# R7KA8P1AD register map
Vendor: Renesas Electronics Corporation; Series: RA8; File version: 1.10.02
CPU: CM85 r0p2, little endian, MPU, FPU, VTOR, 4 interrupt priority bits, 96 interrupts
Registers are 32-bit, read-write, reset 0x0 unless marked. A register's access mark holds for its fields unless they carry their own. Offsets are from the block's base; [hi:lo] are bit positions; {n}, {i} and the like mark numbered series; 'fields as' and 'values as' point back to an identical list.

## PFS_NS — Control Register
Base 0x50400800
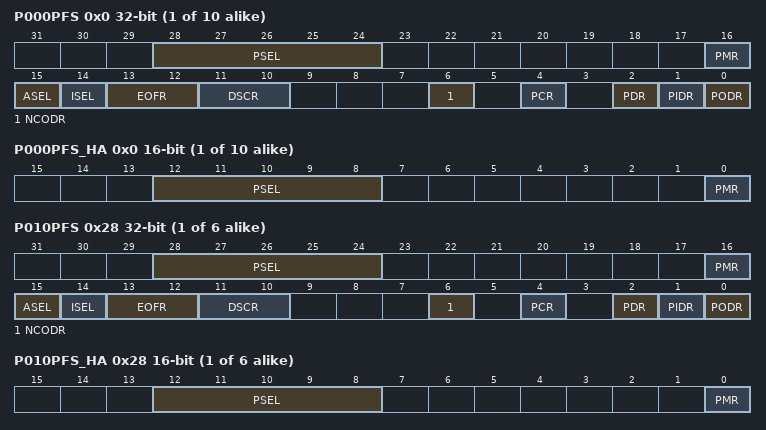
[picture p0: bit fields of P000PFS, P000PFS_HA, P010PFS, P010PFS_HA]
{0x0+4i} P00{i}PFS (i=0..9) — Port 00{i} Pin Function Select Register
  [28:24] PSEL — Peripheral Select
  [16] PMR — Port Mode Control
    0=Used as a general I/O pin; 1=Used as an I/O port for peripheral functions
  [15] ASEL — Analog Input Enable
    0=Not used as an analog pin; 1=Used as an analog pin
  [14] ISEL — IRQ Input Enable
    0=Not used as an IRQn input pin; 1=Used as an IRQn input pin
  [13:12] EOFR — Event on Falling/Event on Rising
    0=Don't care; 1=Detect rising edge; 2=Detect falling edge; 3=Detect both edges
  [11:10] DSCR — Port Drive Capability
    0=Low drive; 1=Middle drive; 2=High-speed high-drive; 3=High drive
  [6] NCODR — N-Channel Open-Drain Control
    0=CMOS output; 1=NMOS open-drain output
  [4] PCR — Pull-up Control
    0=Disable input pull-up; 1=Enable input pull-up
  [2] PDR — Port Direction
    0=Input (functions as an input pin); 1=Output (functions as an output pin)
  [1] PIDR ro — Pmn State
    0=Low level; 1=High level
  [0] PODR — Port Output Data
    0=Low output; 1=High output
{0x0+4i} P00{i}PFS_HA (i=0..9) 16-bit (alternate view of P00{i}PFS) — Port 00{i} Pin Function Select Register
  [12:8] PSEL — Peripheral Select
  [0] PMR — Port Mode Control
    values as P000PFS.PMR
{0x0+4i} P00{i}PFS_BY (i=0..9) 8-bit (alternate view of P00{i}PFS) — Port 00{i} Pin Function Select Register
  [4:0] PSEL — Peripheral Select
{0x0+4i} P0{i}PFS (i=10..15) — Port 0{i} Pin Function Select Register
  fields as P000PFS
{0x0+4i} P0{i}PFS_HA (i=10..15) 16-bit (alternate view of P0{i}PFS) — Port 0{i} Pin Function Select Register
  fields as P000PFS_HA
{0x0+4i} P0{i}PFS_BY (i=10..15) 8-bit (alternate view of P0{i}PFS) — Port 0{i} Pin Function Select Register
  [4:0] PSEL — Peripheral Select
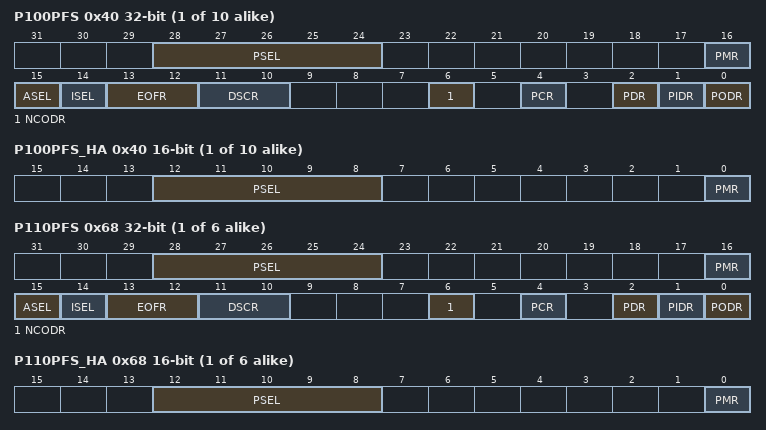
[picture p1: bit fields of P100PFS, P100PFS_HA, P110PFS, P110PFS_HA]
{0x40+4i} P10{i}PFS (i=0..9) — Port 10{i} Pin Function Select Register
  fields as P000PFS
{0x40+4i} P10{i}PFS_HA (i=0..9) 16-bit (alternate view of P10{i}PFS) — Port 10{i} Pin Function Select Register
  fields as P000PFS_HA
{0x40+4i} P10{i}PFS_BY (i=0..9) 8-bit (alternate view of P10{i}PFS) — Port 10{i} Pin Function Select Register
  [4:0] PSEL — Peripheral Select
{0x40+4i} P1{i}PFS (i=10..15) — Port 1{i} Pin Function Select Register
  fields as P000PFS
{0x40+4i} P1{i}PFS_HA (i=10..15) 16-bit (alternate view of P1{i}PFS) — Port 1{i} Pin Function Select Register
  fields as P000PFS_HA
{0x40+4i} P1{i}PFS_BY (i=10..15) 8-bit (alternate view of P1{i}PFS) — Port 1{i} Pin Function Select Register
  [4:0] PSEL — Peripheral Select
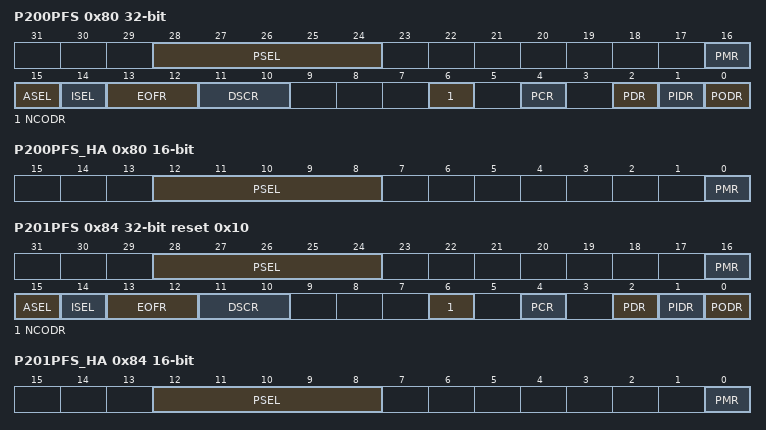
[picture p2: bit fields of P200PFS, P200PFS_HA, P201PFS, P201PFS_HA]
0x80 P200PFS — Port 200 Pin Function Select Register
  fields as P000PFS
0x80 P200PFS_HA 16-bit (alternate view of P200PFS) — Port 200 Pin Function Select Register
  fields as P000PFS_HA
0x80 P200PFS_BY 8-bit (alternate view of P200PFS) — Port 200 Pin Function Select Register
  [4:0] PSEL — Peripheral Select
0x84 P201PFS reset 0x10 — Port 201 Pin Function Select Register
  fields as P000PFS
0x84 P201PFS_HA 16-bit (alternate view of P201PFS) — Port 201 Pin Function Select Register
  fields as P000PFS_HA
0x84 P201PFS_BY 8-bit (alternate view of P201PFS) — Port 201 Pin Function Select Register
  [4:0] PSEL — Peripheral Select
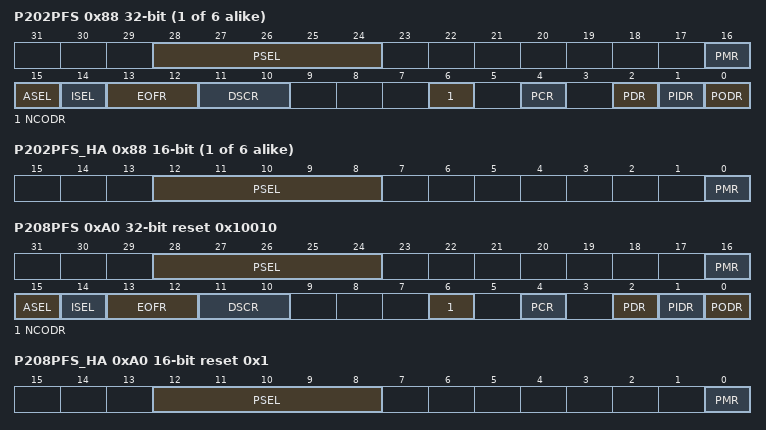
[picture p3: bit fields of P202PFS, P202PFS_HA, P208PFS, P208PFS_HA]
{0x80+4i} P20{i}PFS (i=2..7) — Port 20{i} Pin Function Select Register
  fields as P000PFS
{0x80+4i} P20{i}PFS_HA (i=2..7) 16-bit (alternate view of P20{i}PFS) — Port 20{i} Pin Function Select Register
  fields as P000PFS_HA
{0x80+4i} P20{i}PFS_BY (i=2..7) 8-bit (alternate view of P20{i}PFS) — Port 20{i} Pin Function Select Register
  [4:0] PSEL — Peripheral Select
0xA0 P208PFS reset 0x10010 — Port 208 Pin Function Select Register
  fields as P000PFS
0xA0 P208PFS_HA 16-bit reset 0x1 (alternate view of P208PFS) — Port 208 Pin Function Select Register
  fields as P000PFS_HA
0xA0 P208PFS_BY 8-bit (alternate view of P208PFS) — Port 208 Pin Function Select Register
  [4:0] PSEL — Peripheral Select
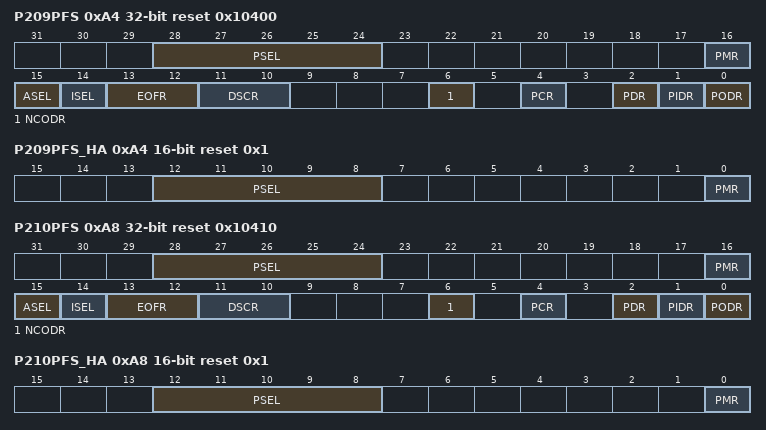
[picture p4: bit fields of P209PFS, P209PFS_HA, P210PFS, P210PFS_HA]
0xA4 P209PFS reset 0x10400 — Port 209 Pin Function Select Register
  fields as P000PFS
0xA4 P209PFS_HA 16-bit reset 0x1 (alternate view of P209PFS) — Port 209 Pin Function Select Register
  fields as P000PFS_HA
0xA4 P209PFS_BY 8-bit (alternate view of P209PFS) — Port 209 Pin Function Select Register
  [4:0] PSEL — Peripheral Select
0xA8 P210PFS reset 0x10410 — Port 210 Pin Function Select Register
  fields as P000PFS
0xA8 P210PFS_HA 16-bit reset 0x1 (alternate view of P210PFS) — Port 210 Pin Function Select Register
  fields as P000PFS_HA
0xA8 P210PFS_BY 8-bit (alternate view of P210PFS) — Port 210 Pin Function Select Register
  [4:0] PSEL — Peripheral Select
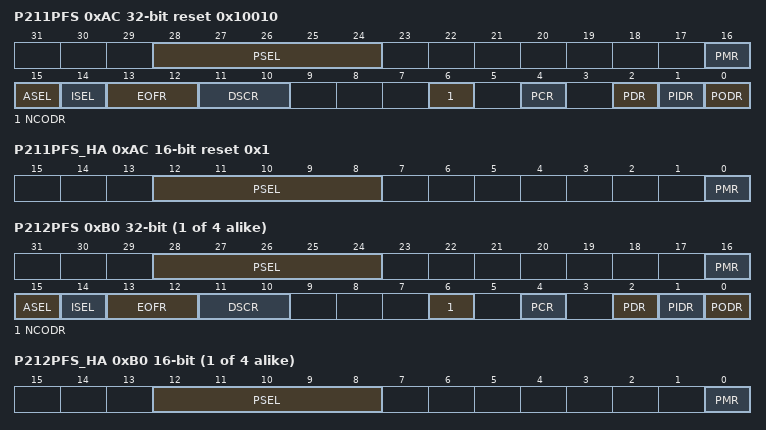
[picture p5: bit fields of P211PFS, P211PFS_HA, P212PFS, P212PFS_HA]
0xAC P211PFS reset 0x10010 — Port 211 Pin Function Select Register
  fields as P000PFS
0xAC P211PFS_HA 16-bit reset 0x1 (alternate view of P211PFS) — Port 211 Pin Function Select Register
  fields as P000PFS_HA
0xAC P211PFS_BY 8-bit (alternate view of P211PFS) — Port 211 Pin Function Select Register
  [4:0] PSEL — Peripheral Select
{0x80+4i} P2{i}PFS (i=12..15) (reset mask 0xFFFFFFFD) — Port 2{i} Pin Function Select Register
  fields as P000PFS
{0x80+4i} P2{i}PFS_HA (i=12..15) 16-bit (alternate view of P2{i}PFS) — Port 2{i} Pin Function Select Register
  fields as P000PFS_HA
{0x80+4i} P2{i}PFS_BY (i=12..15) 8-bit (alternate view of P2{i}PFS) — Port 2{i} Pin Function Select Register
  [4:0] PSEL — Peripheral Select
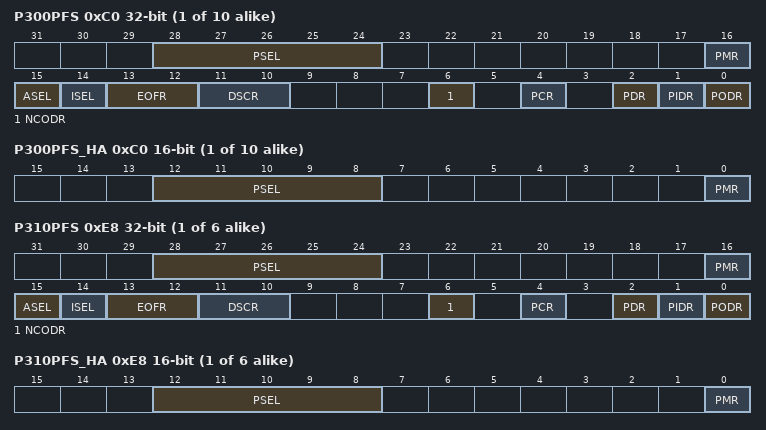
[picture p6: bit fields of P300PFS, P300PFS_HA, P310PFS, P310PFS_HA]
{0xC0+4i} P30{i}PFS (i=0..9) (reset mask 0xFFFFFFFD) — Port 30{i} Pin Function Select Register
  fields as P000PFS
{0xC0+4i} P30{i}PFS_HA (i=0..9) 16-bit (alternate view of P30{i}PFS) — Port 30{i} Pin Function Select Register
  fields as P000PFS_HA
{0xC0+4i} P30{i}PFS_BY (i=0..9) 8-bit (alternate view of P30{i}PFS) — Port 30{i} Pin Function Select Register
  [4:0] PSEL — Peripheral Select
{0xC0+4i} P3{i}PFS (i=10..15) (reset mask 0xFFFFFFFD) — Port 3{i} Pin Function Select Register
  fields as P000PFS
{0xC0+4i} P3{i}PFS_HA (i=10..15) 16-bit (alternate view of P3{i}PFS) — Port 3{i} Pin Function Select Register
  fields as P000PFS_HA
{0xC0+4i} P3{i}PFS_BY (i=10..15) 8-bit (alternate view of P3{i}PFS) — Port 3{i} Pin Function Select Register
  [4:0] PSEL — Peripheral Select
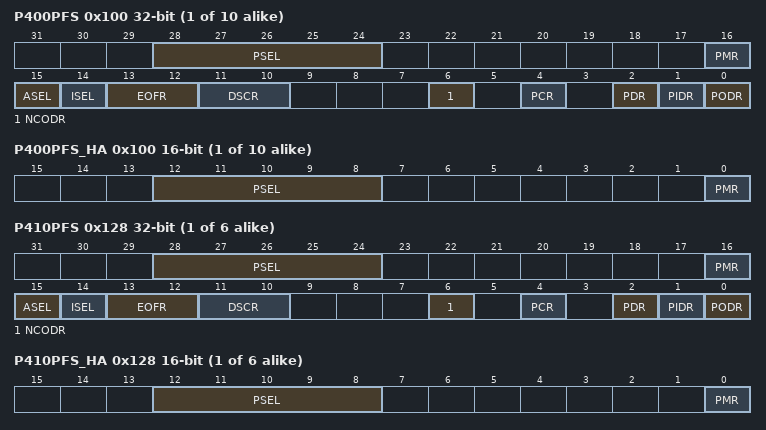
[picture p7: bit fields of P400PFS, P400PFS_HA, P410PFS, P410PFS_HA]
{0x100+4i} P40{i}PFS (i=0..9) (reset mask 0xFFFFFFFD) — Port 40{i} Pin Function Select Register
  fields as P000PFS
{0x100+4i} P40{i}PFS_HA (i=0..9) 16-bit (alternate view of P40{i}PFS) — Port 40{i} Pin Function Select Register
  fields as P000PFS_HA
{0x100+4i} P40{i}PFS_BY (i=0..9) 8-bit (alternate view of P40{i}PFS) — Port 40{i} Pin Function Select Register
  [4:0] PSEL — Peripheral Select
{0x100+4i} P4{i}PFS (i=10..15) (reset mask 0xFFFFFFFD) — Port 4{i} Pin Function Select Register
  fields as P000PFS
{0x100+4i} P4{i}PFS_HA (i=10..15) 16-bit (alternate view of P4{i}PFS) — Port 4{i} Pin Function Select Register
  fields as P000PFS_HA
{0x100+4i} P4{i}PFS_BY (i=10..15) 8-bit (alternate view of P4{i}PFS) — Port 4{i} Pin Function Select Register
  [4:0] PSEL — Peripheral Select
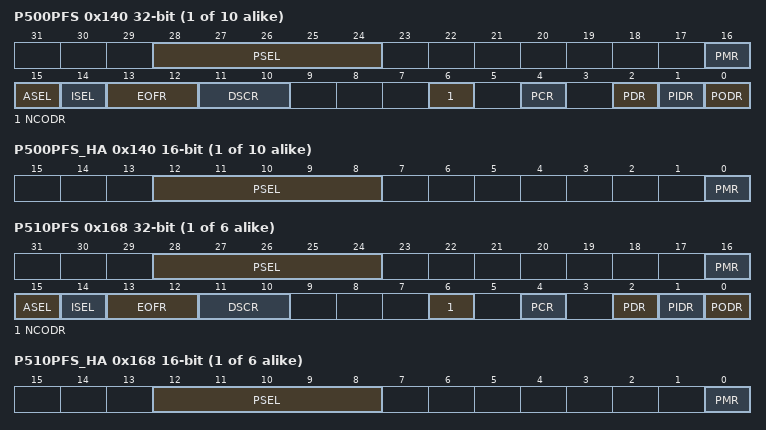
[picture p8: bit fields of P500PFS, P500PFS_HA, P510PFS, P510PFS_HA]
{0x140+4i} P50{i}PFS (i=0..9) (reset mask 0xFFFFFFFD) — Port 50{i} Pin Function Select Register
  fields as P000PFS
{0x140+4i} P50{i}PFS_HA (i=0..9) 16-bit (alternate view of P50{i}PFS) — Port 50{i} Pin Function Select Register
  fields as P000PFS_HA
{0x140+4i} P50{i}PFS_BY (i=0..9) 8-bit (alternate view of P50{i}PFS) — Port 50{i} Pin Function Select Register
  [4:0] PSEL — Peripheral Select
{0x140+4i} P5{i}PFS (i=10..15) (reset mask 0xFFFFFFFD) — Port 5{i} Pin Function Select Register
  fields as P000PFS
{0x140+4i} P5{i}PFS_HA (i=10..15) 16-bit (alternate view of P5{i}PFS) — Port 5{i} Pin Function Select Register
  fields as P000PFS_HA
{0x140+4i} P5{i}PFS_BY (i=10..15) 8-bit (alternate view of P5{i}PFS) — Port 5{i} Pin Function Select Register
  [4:0] PSEL — Peripheral Select
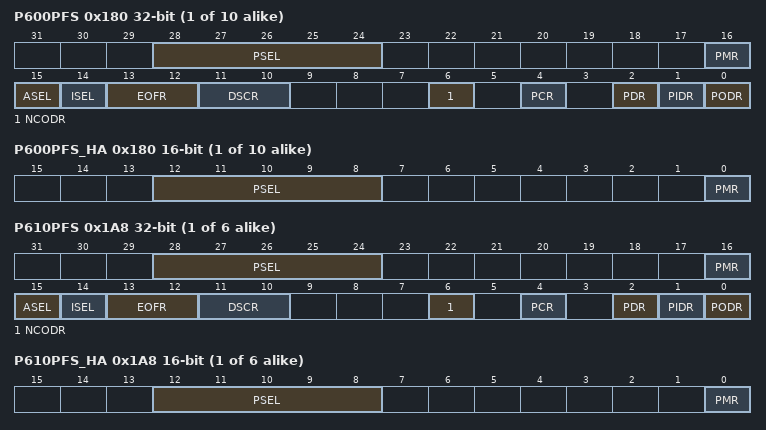
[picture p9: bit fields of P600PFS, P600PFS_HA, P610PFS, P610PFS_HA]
{0x180+4i} P60{i}PFS (i=0..9) (reset mask 0xFFFFFFFD) — Port 60{i} Pin Function Select Register
  fields as P000PFS
{0x180+4i} P60{i}PFS_HA (i=0..9) 16-bit (alternate view of P60{i}PFS) — Port 60{i} Pin Function Select Register
  fields as P000PFS_HA
{0x180+4i} P60{i}PFS_BY (i=0..9) 8-bit (alternate view of P60{i}PFS) — Port 60{i} Pin Function Select Register
  [4:0] PSEL — Peripheral Select
{0x180+4i} P6{i}PFS (i=10..15) (reset mask 0xFFFFFFFD) — Port 6{i} Pin Function Select Register
  fields as P000PFS
{0x180+4i} P6{i}PFS_HA (i=10..15) 16-bit (alternate view of P6{i}PFS) — Port 6{i} Pin Function Select Register
  fields as P000PFS_HA
{0x180+4i} P6{i}PFS_BY (i=10..15) 8-bit (alternate view of P6{i}PFS) — Port 6{i} Pin Function Select Register
  [4:0] PSEL — Peripheral Select
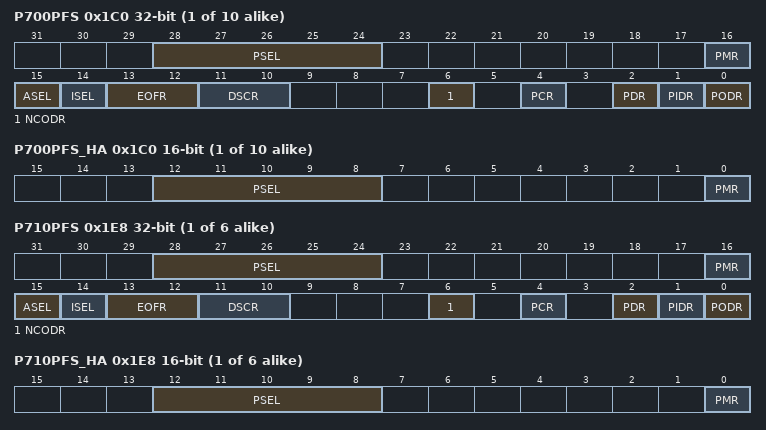
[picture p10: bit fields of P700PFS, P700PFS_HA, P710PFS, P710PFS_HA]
{0x1C0+4i} P70{i}PFS (i=0..9) (reset mask 0xFFFFFFFD) — Port 70{i} Pin Function Select Register
  fields as P000PFS
{0x1C0+4i} P70{i}PFS_HA (i=0..9) 16-bit (alternate view of P70{i}PFS) — Port 70{i} Pin Function Select Register
  fields as P000PFS_HA
{0x1C0+4i} P70{i}PFS_BY (i=0..9) 8-bit (alternate view of P70{i}PFS) — Port 70{i} Pin Function Select Register
  [4:0] PSEL — Peripheral Select
{0x1C0+4i} P7{i}PFS (i=10..15) (reset mask 0xFFFFFFFD) — Port 7{i} Pin Function Select Register
  fields as P000PFS
{0x1C0+4i} P7{i}PFS_HA (i=10..15) 16-bit (alternate view of P7{i}PFS) — Port 7{i} Pin Function Select Register
  fields as P000PFS_HA
{0x1C0+4i} P7{i}PFS_BY (i=10..15) 8-bit (alternate view of P7{i}PFS) — Port 7{i} Pin Function Select Register
  [4:0] PSEL — Peripheral Select
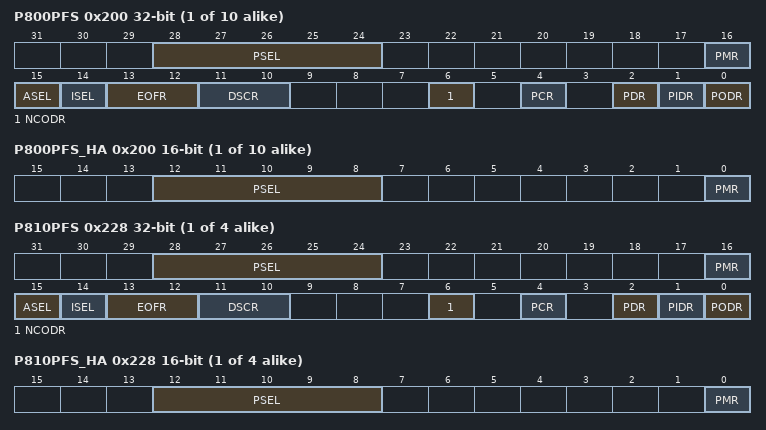
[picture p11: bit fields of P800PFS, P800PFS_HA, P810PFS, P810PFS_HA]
{0x200+4i} P80{i}PFS (i=0..9) (reset mask 0xFFFFFFFD) — Port 80{i} Pin Function Select Register
  fields as P000PFS
{0x200+4i} P80{i}PFS_HA (i=0..9) 16-bit (alternate view of P80{i}PFS) — Port 80{i} Pin Function Select Register
  fields as P000PFS_HA
{0x200+4i} P80{i}PFS_BY (i=0..9) 8-bit (alternate view of P80{i}PFS) — Port 80{i} Pin Function Select Register
  [4:0] PSEL — Peripheral Select
{0x200+4i} P8{i}PFS (i=10..13) (reset mask 0xFFFFFFFD) — Port 8{i} Pin Function Select Register
  fields as P000PFS
{0x200+4i} P8{i}PFS_HA (i=10..13) 16-bit (alternate view of P8{i}PFS) — Port 8{i} Pin Function Select Register
  fields as P000PFS_HA
{0x200+4i} P8{i}PFS_BY (i=10..13) 8-bit (alternate view of P8{i}PFS) — Port 8{i} Pin Function Select Register
  [4:0] PSEL — Peripheral Select
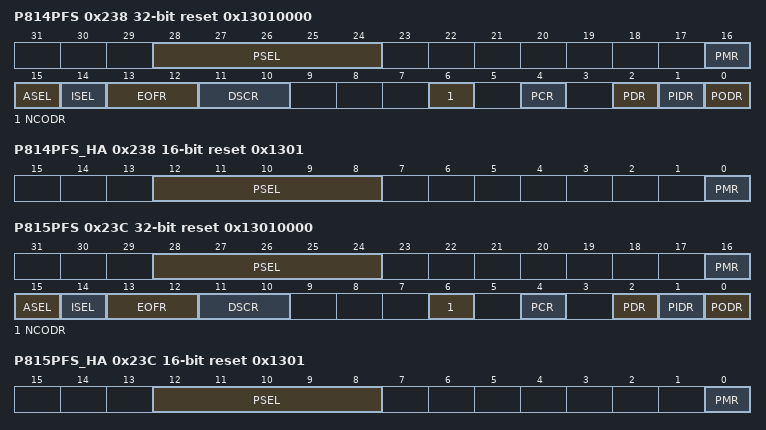
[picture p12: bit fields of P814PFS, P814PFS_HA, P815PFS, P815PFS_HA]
0x238 P814PFS reset 0x13010000 (reset mask 0xFFFFFFFD) — Port 814 Pin Function Select Register
  fields as P000PFS
0x238 P814PFS_HA 16-bit reset 0x1301 (alternate view of P814PFS) — Port 814 Pin Function Select Register
  fields as P000PFS_HA
0x238 P814PFS_BY 8-bit reset 0x13 (alternate view of P814PFS) — Port 814 Pin Function Select Register
  [4:0] PSEL — Peripheral Select
0x23C P815PFS reset 0x13010000 (reset mask 0xFFFFFFFD) — Port 815 Pin Function Select Register
  fields as P000PFS
0x23C P815PFS_HA 16-bit reset 0x1301 (alternate view of P815PFS) — Port 815 Pin Function Select Register
  fields as P000PFS_HA
0x23C P815PFS_BY 8-bit reset 0x13 (alternate view of P815PFS) — Port 815 Pin Function Select Register
  [4:0] PSEL — Peripheral Select
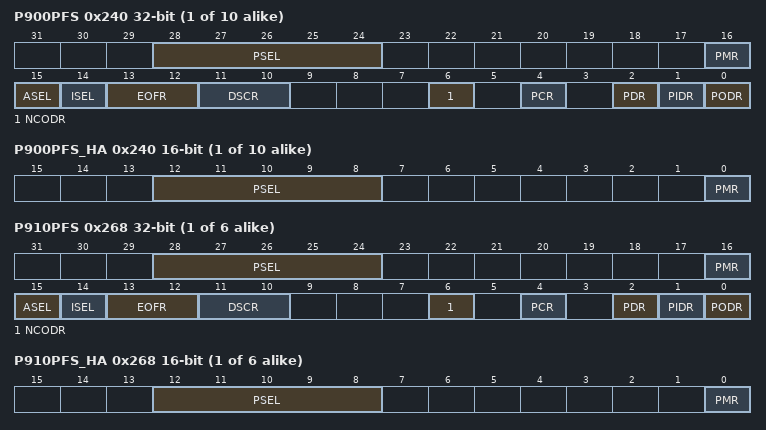
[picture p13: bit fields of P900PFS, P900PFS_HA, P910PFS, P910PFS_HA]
{0x240+4i} P90{i}PFS (i=0..9) (reset mask 0xFFFFFFFD) — Port 90{i} Pin Function Select Register
  fields as P000PFS
{0x240+4i} P90{i}PFS_HA (i=0..9) 16-bit (alternate view of P90{i}PFS) — Port 90{i} Pin Function Select Register
  fields as P000PFS_HA
{0x240+4i} P90{i}PFS_BY (i=0..9) 8-bit (alternate view of P90{i}PFS) — Port 90{i} Pin Function Select Register
  [4:0] PSEL — Peripheral Select
{0x240+4i} P9{i}PFS (i=10..15) (reset mask 0xFFFFFFFD) — Port 9{i} Pin Function Select Register
  fields as P000PFS
{0x240+4i} P9{i}PFS_HA (i=10..15) 16-bit (alternate view of P9{i}PFS) — Port 9{i} Pin Function Select Register
  fields as P000PFS_HA
{0x240+4i} P9{i}PFS_BY (i=10..15) 8-bit (alternate view of P9{i}PFS) — Port 9{i} Pin Function Select Register
  [4:0] PSEL — Peripheral Select
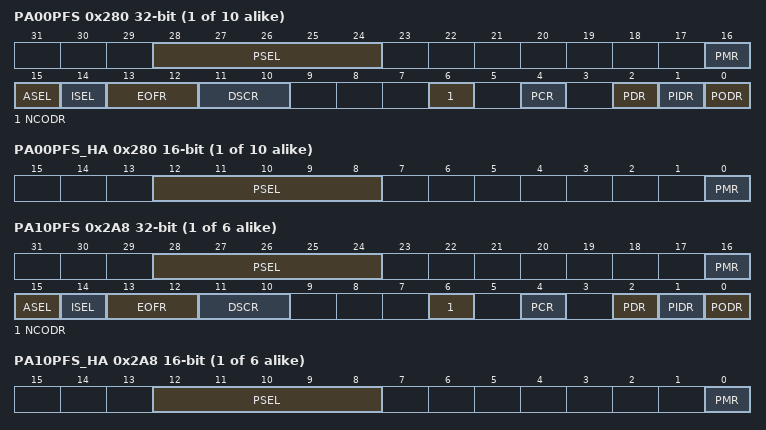
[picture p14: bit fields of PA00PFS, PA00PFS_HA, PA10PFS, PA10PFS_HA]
{0x280+4i} PA0{i}PFS (i=0..9) (reset mask 0xFFFFFFFD) — Port A0{i} Pin Function Select Register
  fields as P000PFS
{0x280+4i} PA0{i}PFS_HA (i=0..9) 16-bit (alternate view of PA0{i}PFS) — Port A0{i} Pin Function Select Register
  fields as P000PFS_HA
{0x280+4i} PA0{i}PFS_BY (i=0..9) 8-bit (alternate view of PA0{i}PFS) — Port A0{i} Pin Function Select Register
  [4:0] PSEL — Peripheral Select
{0x280+4i} PA{i}PFS (i=10..15) (reset mask 0xFFFFFFFD) — Port An Pin Function Select Register
  fields as P000PFS
{0x280+4i} PA{i}PFS_HA (i=10..15) 16-bit (alternate view of PA{i}PFS) — Port An Pin Function Select Register
  fields as P000PFS_HA
{0x280+4i} PA{i}PFS_BY (i=10..15) 8-bit (alternate view of PA{i}PFS) — Port An Pin Function Select Register
  [4:0] PSEL — Peripheral Select
{0x2C0+4i} PB0{i}PFS (i=0..7) (reset mask 0xFFFFFFFD) — Port B0{i} Pin Function Select Register
  fields as P000PFS
{0x2C0+4i} PB0{i}PFS_HA (i=0..7) 16-bit (alternate view of PB0{i}PFS) — Port B0{i} Pin Function Select Register
  fields as P000PFS_HA
{0x2C0+4i} PB0{i}PFS_BY (i=0..7) 8-bit (alternate view of PB0{i}PFS) — Port B0{i} Pin Function Select Register
  [4:0] PSEL — Peripheral Select
{0x300+4i} PC0{i}PFS (i=0..9) (reset mask 0xFFFFFFFD) — Port C0{i} Pin Function Select Register
  fields as P000PFS
{0x300+4i} PC0{i}PFS_HA (i=0..9) 16-bit (alternate view of PC0{i}PFS) — Port C0{i} Pin Function Select Register
  fields as P000PFS_HA
{0x300+4i} PC0{i}PFS_BY (i=0..9) 8-bit (alternate view of PC0{i}PFS) — Port C0{i} Pin Function Select Register
  [4:0] PSEL — Peripheral Select
{0x300+4i} PC{i}PFS (i=10..15) (reset mask 0xFFFFFFFD) — Port Cn Pin Function Select Register
  fields as P000PFS
{0x300+4i} PC{i}PFS_HA (i=10..15) 16-bit (alternate view of PC{i}PFS) — Port Cn Pin Function Select Register
  fields as P000PFS_HA
{0x300+4i} PC{i}PFS_BY (i=10..15) 8-bit (alternate view of PC{i}PFS) — Port Cn Pin Function Select Register
  [4:0] PSEL — Peripheral Select
{0x340+4i} PD0{i}PFS (i=0..7) (reset mask 0xFFFFFFFD) — Port D0{i} Pin Function Select Register
  fields as P000PFS
{0x340+4i} PD0{i}PFS_HA (i=0..7) 16-bit (alternate view of PD0{i}PFS) — Port D0{i} Pin Function Select Register
  fields as P000PFS_HA
{0x340+4i} PD0{i}PFS_BY (i=0..7) 8-bit (alternate view of PD0{i}PFS) — Port D0{i} Pin Function Select Register
  [4:0] PSEL — Peripheral Select
0x500 PFENET 8-bit — Ethernet Control Register
  [5] ETHIOMD1 — Ethernet I/O Mode Setting ch1
    0=GMII mode (ESWM channel 1); 1=MII mode (ESWM channel 1)
  [4] ETHIOMD0 — Ethernet I/O Mode Setting ch0
    0=GMII mode (ESWM channel 0); 1=MII mode (ESWM channel 0)
0x50C PWPR_NS 8-bit reset 0x80 — Write-Protect Register for Non-secure
  [7] B0WI — PFSWE Bit Write Disable
    0=Writing to the PFSWE bit is enabled; 1=Writing to the PFSWE bit is disabled
  [6] PFSWE — PmnPFS Register Write Enable
    0=Writing to the PmnPFS register is disabled; 1=Writing to the PmnPFS register is enabled
{0x530+4i} P{i}SAR (i=0..9) 16-bit — Port Security Attribution Register
  [15:0] PMNSA — Pmn Security Attribution
    0=Secure; 1=Non Secure
0x558 P{x}SAR (x=A,B; step 0x4) 16-bit — Port Security Attribution Register
  [15:0] PMNSA — Pmn Security Attribution
    0=Secure; 1=Non Secure
